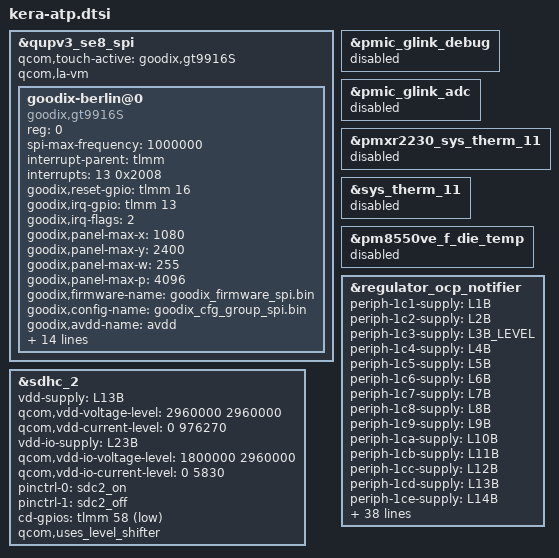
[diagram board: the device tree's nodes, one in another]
// SPDX-License-Identifier: BSD-3-Clause
/*
 * Copyright (c) 2024-2025 Qualcomm Innovation Center, Inc. All rights reserved.
 */
#include <dt-bindings/gpio/gpio.h>
#include "kera_ufs4.dtsi"

&qupv3_se8_spi {
	#address-cells = <1>;
	#size-cells = <0>;

	status = "ok";
	qcom,touch-active = "goodix,gt9916S";
	qcom,la-vm;

	goodix-berlin@0 {
		compatible = "goodix,gt9916S";
		reg = <0>;
		spi-max-frequency = <1000000>;
		interrupt-parent = <&tlmm>;
		interrupts = <13 0x2008>;
		goodix,reset-gpio = <&tlmm 16 0x00>;
		goodix,irq-gpio = <&tlmm 13 0x2008>;
		goodix,irq-flags = <2>;
		goodix,panel-max-x = <1080>;
		goodix,panel-max-y = <2400>;
		goodix,panel-max-w = <255>;
		goodix,panel-max-p = <4096>;
		goodix,firmware-name = "goodix_firmware_spi.bin";
		goodix,config-name = "goodix_cfg_group_spi.bin";
		goodix,avdd-name = "avdd";
		goodix,iovdd-name = "iovdd";
		avdd-supply = <&L22B>;
		iovdd-supply = <&L8B>;
		goodix,touch-type = "primary";
		goodix,qts_en;

		qts,trusted-touch-mode = "vm_mode";
		qts,touch-environment = "pvm";
		qts,trusted-touch-type = "primary";
		qts,trusted-touch-spi-irq = <653>;
		qts,trusted-touch-io-bases = <0x880000>;
		qts,trusted-touch-io-sizes = <0x1000>;
		qts,trusted-touch-vm-gpio-list = <&tlmm 0 0 &tlmm 1 0 &tlmm 2 0
						&tlmm 3 0 &tlmm 16 0 &tlmm 13 0x2008>;
	};
};

&sdhc_2 {
	vdd-supply = <&L13B>;
	qcom,vdd-voltage-level = <2960000 2960000>;
	qcom,vdd-current-level = <0 976270>;

	vdd-io-supply = <&L23B>;
	qcom,vdd-io-voltage-level = <1800000 2960000>;
	qcom,vdd-io-current-level = <0 5830>;

	pinctrl-names = "default", "sleep";
	pinctrl-0 = <&sdc2_on>;
	pinctrl-1 = <&sdc2_off>;

	cd-gpios = <&tlmm 58 GPIO_ACTIVE_LOW>;

	qcom,uses_level_shifter;

	status = "ok";
};

&pmic_glink_debug {
	status = "disabled";
};

&pmic_glink_adc {
	status = "disabled";
};

&pmxr2230_sys_therm_11 {
	status = "disabled";
};

&sys_therm_11 {
	status = "disabled";
};

&pm8550ve_f_die_temp {
	status = "disabled";
};

&regulator_ocp_notifier {
	periph-1c1-supply = <&L1B>;
	periph-1c2-supply = <&L2B>;
	periph-1c3-supply = <&L3B_LEVEL>;
	periph-1c4-supply = <&L4B>;
	periph-1c5-supply = <&L5B>;
	periph-1c6-supply = <&L6B>;
	periph-1c7-supply = <&L7B>;
	periph-1c8-supply = <&L8B>;
	periph-1c9-supply = <&L9B>;
	periph-1ca-supply = <&L10B>;
	periph-1cb-supply = <&L11B>;
	periph-1cc-supply = <&L12B>;
	periph-1cd-supply = <&L13B>;
	periph-1ce-supply = <&L14B>;
	periph-1cf-supply = <&L15B>;
	periph-1d0-supply = <&L16B>;
	periph-1d1-supply = <&L17B>;
	periph-1d2-supply = <&L18B>;
	periph-1d3-supply = <&L19B>;
	periph-1d4-supply = <&L20B>;
	periph-1d5-supply = <&L21B>;
	periph-1d6-supply = <&L22B>;
	periph-1d7-supply = <&L23B>;
	periph-19b-supply = <&S1B>;
	periph-19e-supply = <&S2B>;
	periph-1a1-supply = <&S3B>;
	periph-1a2-supply = <&S4B>;
	periph-1e4-supply = <&BOB>;
	periph-3c1-supply = <&L1D>;
	periph-3c2-supply = <&L2D>;
	periph-3c3-supply = <&L3D_LEVEL>;
	periph-39b-supply = <&S1D_LEVEL>;
	periph-3a1-supply = <&S3D_LEVEL>;
	periph-3a2-supply = <&S4D_LEVEL>;
	periph-3a3-supply = <&S5D_LEVEL>;
	periph-6c1-supply = <&L1G>;
	periph-6c2-supply = <&L2G>;
	periph-6c3-supply = <&L3G>;
	periph-c40-supply = <&L1M>;
	periph-c41-supply = <&L2M>;
	periph-c42-supply = <&L3M>;
	periph-c43-supply = <&L4M>;
	periph-c44-supply = <&L5M>;
	periph-c45-supply = <&L6M>;
	periph-c46-supply = <&L7M>;
	periph-d40-supply = <&L1N>;
	periph-d41-supply = <&L2N>;
	periph-d42-supply = <&L3N>;
	periph-d43-supply = <&L4N>;
	periph-d44-supply = <&L5N>;
	periph-d45-supply = <&L6N>;
	periph-d46-supply = <&L7N>;
};
